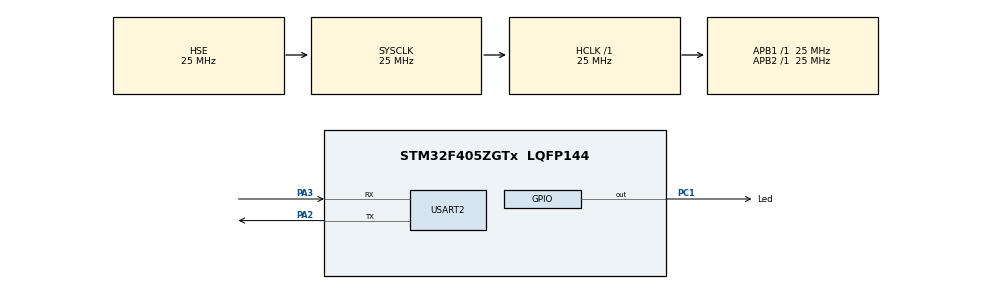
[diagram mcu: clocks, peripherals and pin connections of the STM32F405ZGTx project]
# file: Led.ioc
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FREERTOS.Tasks01=Task1,0,128,StartTask1,Default,NULL,Dynamic,NULL,NULL;Task2,0,128,StartTask2,Default,NULL,Dynamic,NULL,NULL
Mcu.Family=STM32F4
Mcu.Name=STM32F405ZGTx
Mcu.Package=LQFP144
NVIC.PriorityGroup=NVIC_PRIORITYGROUP_4
NVIC.TIM1_UP_TIM10_IRQn=true\:0\:0\:false\:false\:true\:false\:false\:true
NVIC.TimeBase=TIM1_UP_TIM10_IRQn
NVIC.TimeBaseIP=TIM1
NVIC.USART2_IRQn=true\:5\:0\:false\:false\:true\:true\:true\:true
PA2.GPIO_PuPd=GPIO_PULLUP
PA2.Mode=Asynchronous
PA2.Signal=USART2_TX
PA3.GPIO_PuPd=GPIO_PULLUP
PA3.Mode=Asynchronous
PA3.Signal=USART2_RX
PC1.GPIO_Label=Led
PC1.Signal=GPIO_Output
PH0-OSC_IN.Mode=HSE-External-Oscillator
PH0-OSC_IN.Signal=RCC_OSC_IN
PH1-OSC_OUT.Mode=HSE-External-Oscillator
PH1-OSC_OUT.Signal=RCC_OSC_OUT
ProjectManager.HeapSize=0x200
ProjectManager.StackSize=0x400
ProjectManager.TargetToolchain=MDK-ARM V5.27
RCC.AHBFreq_Value=25000000
RCC.APB1Freq_Value=25000000
RCC.APB1TimFreq_Value=25000000
RCC.APB2Freq_Value=25000000
RCC.APB2TimFreq_Value=25000000
RCC.CortexFreq_Value=25000000
RCC.HCLKFreq_Value=25000000
RCC.HSE_VALUE=25000000
RCC.HSI_VALUE=16000000
RCC.LSE_VALUE=32768
RCC.SYSCLKFreq_VALUE=25000000
RCC.SYSCLKSource=RCC_SYSCLKSOURCE_HSE
RCC.VCOOutputFreq_Value=192000000
USART2.VirtualMode=VM_ASYNC
VP_FREERTOS_VS_CMSIS_V1.Mode=CMSIS_V1
VP_SYS_VS_tim1.Mode=TIM1
board=custom

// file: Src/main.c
/* USER CODE BEGIN Header */
/**
  ******************************************************************************
  * @file           : main.c
  * @brief          : Main program body
  ******************************************************************************
  * @attention
  *
  * <h2><center>&copy; Copyright (c) 2020 STMicroelectronics.
  * All rights reserved.</center></h2>
  *
  * This software component is licensed by ST under Ultimate Liberty license
  * SLA0044, the "License"; You may not use this file except in compliance with
  * the License. You may obtain a copy of the License at:
  *                             www.st.com/SLA0044
  *
  ******************************************************************************
  */
/* USER CODE END Header */

#include "main.h"
#include "cmsis_os.h"
#include "usart.h"
#include "gpio.h"

void SystemClock_Config(void);
void MX_FREERTOS_Init(void);

int main(void)
{

  /* MCU Configuration--------------------------------------------------------*/

  /* Reset of all peripherals, Initializes the Flash interface and the Systick. */
  HAL_Init();

  /* Configure the system clock */
  SystemClock_Config();

  /* Initialize all configured peripherals */
  MX_GPIO_Init();
  MX_USART2_UART_Init();

  /* Call init function for freertos objects (in freertos.c) */
  MX_FREERTOS_Init();

  /* Start scheduler */
  osKernelStart();

  /* We should never get here as control is now taken by the scheduler */

  /* Infinite loop */
  while (1)
  {

  }
}

void SystemClock_Config(void)
{
  RCC_OscInitTypeDef RCC_OscInitStruct = {0};
  RCC_ClkInitTypeDef RCC_ClkInitStruct = {0};

  /** Configure the main internal regulator output voltage
  */
  __HAL_RCC_PWR_CLK_ENABLE();
  __HAL_PWR_VOLTAGESCALING_CONFIG(PWR_REGULATOR_VOLTAGE_SCALE1);
  /** Initializes the CPU, AHB and APB busses clocks
  */
  RCC_OscInitStruct.OscillatorType = RCC_OSCILLATORTYPE_HSE;
  RCC_OscInitStruct.HSEState = RCC_HSE_ON;
  RCC_OscInitStruct.PLL.PLLState = RCC_PLL_NONE;
  if (HAL_RCC_OscConfig(&RCC_OscInitStruct) != HAL_OK)
  {
    Error_Handler();
  }
  /** Initializes the CPU, AHB and APB busses clocks
  */
  RCC_ClkInitStruct.ClockType = RCC_CLOCKTYPE_HCLK|RCC_CLOCKTYPE_SYSCLK
                              |RCC_CLOCKTYPE_PCLK1|RCC_CLOCKTYPE_PCLK2;
  RCC_ClkInitStruct.SYSCLKSource = RCC_SYSCLKSOURCE_HSE;
  RCC_ClkInitStruct.AHBCLKDivider = RCC_SYSCLK_DIV1;
  RCC_ClkInitStruct.APB1CLKDivider = RCC_HCLK_DIV1;
  RCC_ClkInitStruct.APB2CLKDivider = RCC_HCLK_DIV1;

  if (HAL_RCC_ClockConfig(&RCC_ClkInitStruct, FLASH_LATENCY_0) != HAL_OK)
  {
    Error_Handler();
  }
}

void HAL_TIM_PeriodElapsedCallback(TIM_HandleTypeDef *htim)
{
  if (htim->Instance == TIM1) {
    HAL_IncTick();
  }
}

void Error_Handler(void)
{
}

/************************ (C) COPYRIGHT STMicroelectronics *****END OF FILE****/

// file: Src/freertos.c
/* USER CODE BEGIN Header */
/**
  ******************************************************************************
  * File Name          : freertos.c
  * Description        : Code for freertos applications
  ******************************************************************************
  * @attention
  *
  * <h2><center>&copy; Copyright (c) 2020 STMicroelectronics.
  * All rights reserved.</center></h2>
  *
  * This software component is licensed by ST under Ultimate Liberty license
  * SLA0044, the "License"; You may not use this file except in compliance with
  * the License. You may obtain a copy of the License at:
  *                             www.st.com/SLA0044
  *
  ******************************************************************************
  */
/* USER CODE END Header */

#include "FreeRTOS.h"
#include "task.h"
#include "main.h"
#include "cmsis_os.h"
#include "usart.h"

/* USER CODE BEGIN PD */
 uint8_t  rx_buffer[10]; //array for receiving
void HAL_UART_RxCpltCallback(UART_HandleTypeDef *huart)
{
	void StartTask1();
}
/* USER CODE END PD */

osThreadId Task1Handle;
osThreadId Task2Handle;

void StartTask1(void const * argument);
void StartTask2(void const * argument);

void MX_FREERTOS_Init(void); /* (MISRA C 2004 rule 8.1) */

/* GetIdleTaskMemory prototype (linked to static allocation support) */
void vApplicationGetIdleTaskMemory( StaticTask_t **ppxIdleTaskTCBBuffer, StackType_t **ppxIdleTaskStackBuffer, uint32_t *pulIdleTaskStackSize );

/* USER CODE BEGIN GET_IDLE_TASK_MEMORY */
static StaticTask_t xIdleTaskTCBBuffer;
static StackType_t xIdleStack[configMINIMAL_STACK_SIZE];

void vApplicationGetIdleTaskMemory( StaticTask_t **ppxIdleTaskTCBBuffer, StackType_t **ppxIdleTaskStackBuffer, uint32_t *pulIdleTaskStackSize )
{
  *ppxIdleTaskTCBBuffer = &xIdleTaskTCBBuffer;
  *ppxIdleTaskStackBuffer = &xIdleStack[0];
  *pulIdleTaskStackSize = configMINIMAL_STACK_SIZE;
  /* place for user code */
}
/* USER CODE END GET_IDLE_TASK_MEMORY */

void MX_FREERTOS_Init(void) {

  /* Create the thread(s) */
  /* definition and creation of Task1 */
  osThreadDef(Task1, StartTask1, osPriorityNormal, 0, 128);
  Task1Handle = osThreadCreate(osThread(Task1), NULL);

  /* definition and creation of Task2 */
  osThreadDef(Task2, StartTask2, osPriorityNormal, 0, 128);
  Task2Handle = osThreadCreate(osThread(Task2), NULL);

}

void StartTask1(void const * argument)
{
  /* USER CODE BEGIN StartTask1 */
  /* Infinite loop */
  for(;;)
  {
		HAL_UART_Transmit(&huart2, rx_buffer,1, 100);
		if(rx_buffer[0]=='0')
			{
				HAL_GPIO_WritePin(Led_GPIO_Port,Led_Pin,GPIO_PIN_SET);
			}
		if(rx_buffer[0]=='1')
			{
				HAL_GPIO_WritePin(Led_GPIO_Port,Led_Pin,GPIO_PIN_RESET);
			}
    osDelay(1);
  }
  /* USER CODE END StartTask1 */
}

void StartTask2(void const * argument)
{
  /* USER CODE BEGIN StartTask2 */
  /* Infinite loop */
  for(;;)
  {
		HAL_UART_Receive_IT(&huart2, rx_buffer, 1);
    osDelay(1);
  }
  /* USER CODE END StartTask2 */
}

/************************ (C) COPYRIGHT STMicroelectronics *****END OF FILE****/
